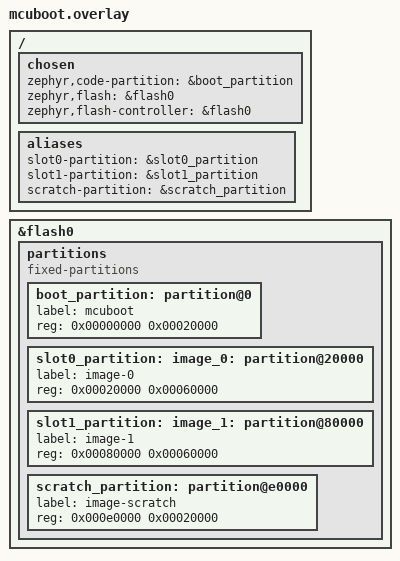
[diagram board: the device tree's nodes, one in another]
/ {
	chosen {
		zephyr,code-partition = &boot_partition;
		zephyr,flash = &flash0;
		zephyr,flash-controller = &flash0;
	};

	aliases {
		slot0-partition = &slot0_partition;
		slot1-partition = &slot1_partition;
		scratch-partition = &scratch_partition;
	};
};

&flash0 {
	status = "okay";

	partitions {
		compatible = "fixed-partitions";
		#address-cells = <1>;
		#size-cells = <1>;

		/* 128KB for MCUboot */
		boot_partition: partition@0 {
			label = "mcuboot";
			reg = <0x00000000 0x00020000>;
		};

		/* 384KB for Slot 0 
		   NOTE: We add 'image_0' and 'image_0_alt' labels to help CMake find it */
		slot0_partition: image_0: image_0_alt: partition@20000 {
			label = "image-0";
			reg = <0x00020000 0x00060000>;
		};

		/* 384KB for Slot 1 */
		slot1_partition: image_1: image_1_alt: partition@80000 {
			label = "image-1";
			reg = <0x00080000 0x00060000>;
		};

		/* 128KB for Scratch */
		scratch_partition: partition@e0000 {
			label = "image-scratch";
			reg = <0x000e0000 0x00020000>;
		};
	};
};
